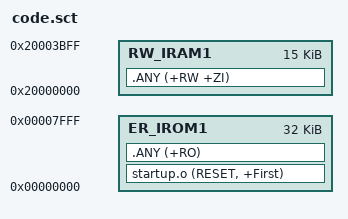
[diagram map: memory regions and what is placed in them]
; 32 KiB code BRAM; the SD cache occupies the last 1 KiB of data BRAM.
; 15 KiB data/stack plus 1 KiB SD cache in the 16 KiB data BRAM.
; The cache starts at ART_CACHE_ADDRESS in appearance.h and is writable.
LR_IROM1 0x00000000 0x00008000 {
 ER_IROM1 0x00000000 0x00008000 {
  startup.o (RESET, +First)
  .ANY (+RO)
 }
 RW_IRAM1 0x20000000 0x00003c00 {
  .ANY (+RW +ZI)
 }
}
